# STM32MP21_CM33 register map
File version: 0.4
CPU: CM33 r0p1, little endian, MPU, FPU, vendor SysTick, 8 interrupt priority bits
Registers are 32-bit, read-write, reset 0x0 unless marked. A register's access mark holds for its fields unless they carry their own. Offsets are from the block's base; [hi:lo] are bit positions.

## IWDG1 — IWDG address block description
Base 0x44010000
Same registers: IWDG2 0x44020000, IWDG3 0x44030000, IWDG4 0x44040000, IWDG1_S 0x54010000, IWDG2_S 0x54020000, IWDG3_S 0x54030000, IWDG4_S 0x54040000
0x00 IWDG_KR wo — IWDG key register
  [15:0] KEY — Key value (write only, read 0x0000)
0x04 IWDG_PR reset 0xF — IWDG prescaler register
  [3:0] PR — Prescaler divider
    0=divider / 4; 1=divider / 8; 2=divider / 16; 3=divider / 32; 4=divider / 64; 5=divider / 128; 6=divider / 256; 7=divider / 512
0x08 IWDG_RLR reset 0xFFF — IWDG reload register
  [11:0] RL — Watchdog counter reload value
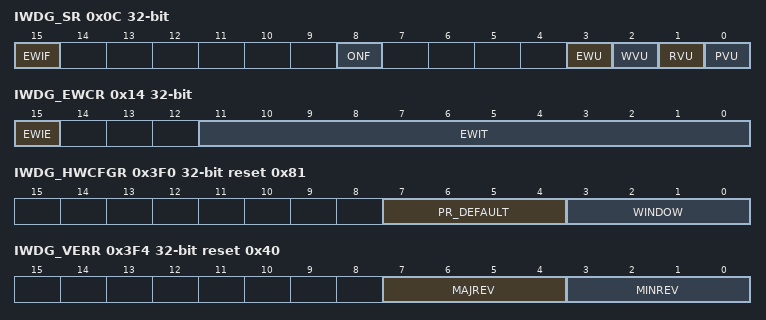
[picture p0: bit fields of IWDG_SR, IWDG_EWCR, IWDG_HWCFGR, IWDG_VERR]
0x0C IWDG_SR ro — IWDG status register
  [15] EWIF — Watchdog early interrupt flag
  [8] ONF — Watchdog enable status bit
    0=The IWDG is not activated; 1=The IWDG is activated and needs to be refreshed regularly by the application
  [3] EWU — Watchdog interrupt comparator value update
  [2] WVU — Watchdog counter window value update
  [1] RVU — Watchdog counter reload value update
  [0] PVU — Watchdog prescaler value update
0x10 IWDG_WINR reset 0xFFF — IWDG window register
  [11:0] WIN — Watchdog counter window value
0x14 IWDG_EWCR — IWDG early wake-up interrupt register
  [15] EWIE — Watchdog early interrupt enable
    0=The early interrupt interface is disabled; 1=The early interrupt interface is enabled
  [11:0] EWIT — Watchdog counter window value
0x18 IWDG_ICR — IWDG interrupt clear register
  [15] EWIC — Watchdog early interrupt acknowledge
0x3F0 IWDG_HWCFGR ro reset 0x81 — IWDG hardware configuration register
  [7:4] PR_DEFAULT — Prescaler default value
    0=Prescaler (PR[3:0]) default value after reset is 0000'; 1=Prescaler (PR[3:0]) default value after reset is 0001'; 2=Prescaler (PR[3:0]) default value after reset is 0010'; 3=Prescaler (PR[3:0]) default value after reset is 0011'; 4=Prescaler (PR[3:0]) default value after reset is 0100'; 5=Prescaler (PR[3:0]) default value after reset is 0101'; 6=Prescaler (PR[3:0]) default value after reset is 0110'; 7=Prescaler (PR[3:0]) default value after reset is 0111'
  [3:0] WINDOW — Support of Window function
    0=Window option disabled; 1=Window option enabled
0x3F4 IWDG_VERR ro reset 0x40 — IWDG version register
  [7:4] MAJREV — IWDG major revision
  [3:0] MINREV — IWDG minor revision
0x3F8 IWDG_IDR ro reset 0x120041 — IWDG identification register
  [31:0] ID — IWDG identifier
0x3FC IWDG_SIDR ro reset 0xA3C5DD01 — IWDG size identification register
  [31:0] SID — IWDG size identifier

## PKA — PKA register blank and RAM
Base 0x42032000
Same registers: PKA_S 0x52032000
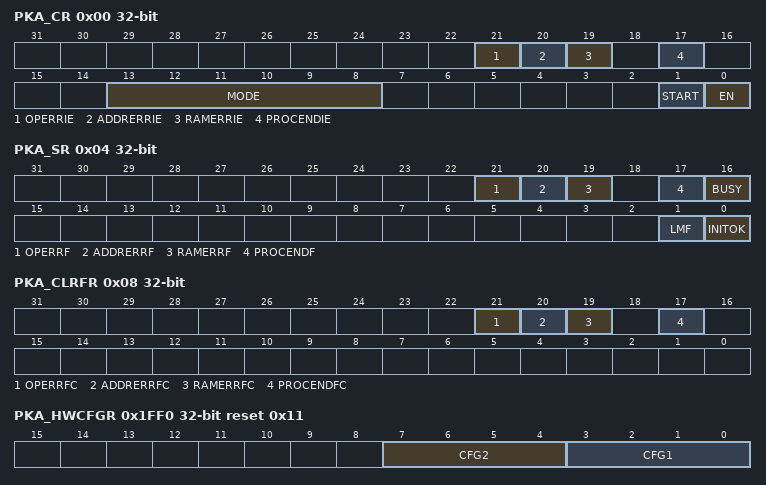
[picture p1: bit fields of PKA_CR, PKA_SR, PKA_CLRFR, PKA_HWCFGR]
0x00 PKA_CR — PKA control register
  [21] OPERRIE — Operation error interrupt enable
    0=No interrupt is generated when OPERRF flag is set in PKA_SR; 1=An interrupt is generated when OPERRF flag is set in PKA_SR
  [20] ADDRERRIE — Address error interrupt enable
    0=No interrupt is generated when ADDRERRF flag is set in PKA_SR; 1=An interrupt is generated when ADDRERRF flag is set in PKA_SR
  [19] RAMERRIE — RAM error interrupt enable
    0=No interrupt is generated when RAMERRF flag is set in PKA_SR; 1=An interrupt is generated when RAMERRF flag is set in PKA_SR
  [17] PROCENDIE — End of operation interrupt enable
    0=No interrupt is generated when PROCENDF flag is set in PKA_SR; 1=An interrupt is generated when PROCENDF flag is set in PKA_SR
  [13:8] MODE — PKA operation code
    0=Montgomery parameter computation then modular exponentiation; 1=Montgomery parameter computation only; 2=Modular exponentiation only (Montgomery parameter must be loaded first); 3=Modular exponentiation (protected, used when manipulating secrets); 32=Montgomery parameter computation then ECC scalar multiplication (protected); 36=ECDSA sign (protected); 38=ECDSA verification; 40=Point on elliptic curve Fp check; 7=RSA CRT exponentiation; 8=Modular inversion; 9=Arithmetic addition; 10=Arithmetic subtraction; 11=Arithmetic multiplication; 12=Arithmetic comparison; 13=Modular reduction; 14=Modular addition; 15=Modular subtraction; 16=Montgomery multiplication; 35=ECC complete addition; 39=ECC double base ladder; 47=ECC projective to affine
  [1] START — start the operation
  [0] EN — PKA enable
    0=Disable PKA; 1=Enable PKA
0x04 PKA_SR ro — PKA status register
  [21] OPERRF — Operation error flag
    0=No event error; 1=An illegal or unknown operation has been selected in PKA_CR register
  [20] ADDRERRF — Address error flag
    0=No address error; 1=Address access is out of range (unmapped address)
  [19] RAMERRF — PKA RAM error flag
    0=No PKA RAM access error; 1=An AHB access to the PKA RAM occurred while the PKA core was computing and using its internal RAM (AHB PKA_RAM access are not allowed while PKA operation is in progress)
  [17] PROCENDF — PKA end of operation flag
    0=Operation in progress; 1=PKA operation is completed
  [16] BUSY — Busy flag
    0=No operation is in progress (default); 1=An operation is in progress
  [1] LMF — Limited mode flag
    0=All values documented in MODE bit field can be used; 1=Only ECDSA verification (MODE = 0x26) is supported by the PKA
  [0] INITOK — PKA initialization OK
    0=PKA is not initialized correctly; 1=PKA is initialized correctly and can be used normally
0x08 PKA_CLRFR wo — PKA clear flag register
  [21] OPERRFC — Clear operation error flag
    0=No action; 1=Clear the OPERRF flag in PKA_SR
  [20] ADDRERRFC — Clear address error flag
    0=No action; 1=Clear the ADDRERRF flag in PKA_SR
  [19] RAMERRFC — Clear PKA RAM error flag
    0=No action; 1=Clear the RAMERRF flag in PKA_SR
  [17] PROCENDFC — Clear PKA end of operation flag
    0=No action; 1=Clear the PROCENDF flag in PKA_SR
0x1FF0 PKA_HWCFGR ro reset 0x11 — PKA hardware configuration register
  [7:4] CFG2 — HW Generic 2
  [3:0] CFG1 — HW Generic 2
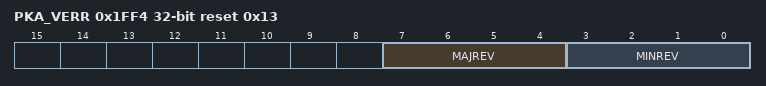
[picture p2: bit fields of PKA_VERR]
0x1FF4 PKA_VERR ro reset 0x13 — PKA version register
  [7:4] MAJREV — Major revision
  [3:0] MINREV — Minor revision
0x1FF8 PKA_IPIDR ro reset 0x170072 — PKA identification register
  [31:0] ID — Identification code
0x1FFC PKA_SIDR ro reset 0xA3C5DD08 — PKA size identification register
  [31:0] SID — Size identification code
